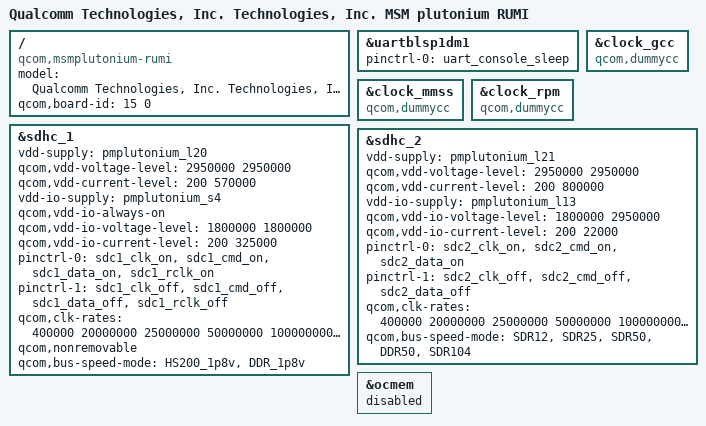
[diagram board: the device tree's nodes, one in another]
/* Copyright (c) 2013-2014, The Linux Foundation. All rights reserved.
 *
 * This program is free software; you can redistribute it and/or modify
 * it under the terms of the GNU General Public License version 2 and
 * only version 2 as published by the Free Software Foundation.
 *
 * This program is distributed in the hope that it will be useful,
 * but WITHOUT ANY WARRANTY; without even the implied warranty of
 * MERCHANTABILITY or FITNESS FOR A PARTICULAR PURPOSE.  See the
 * GNU General Public License for more details.
 */


/dts-v1/;

/memreserve/ 0x06000000 0x00001000;

#include "msmplutonium.dtsi"
#include "msmplutonium-pinctrl.dtsi"
/ {
	model = "Qualcomm Technologies, Inc. Technologies, Inc. MSM plutonium RUMI";
	compatible = "qcom,msmplutonium-rumi", "qcom,msmplutonium", "qcom,rumi";
	qcom,board-id = <15 0>;
};

&uartblsp1dm1 {
	status = "ok";
	pinctrl-names = "default";
	pinctrl-0 = <&uart_console_sleep>;
};

&clock_gcc {
	compatible = "qcom,dummycc";
	#clock-cells = <1>;
};

&clock_mmss {
	compatible = "qcom,dummycc";
	#clock-cells = <1>;
};

&clock_rpm {
	compatible = "qcom,dummycc";
	#clock-cells = <1>;
};

&sdhc_1 {
	vdd-supply = <&pmplutonium_l20>;
	qcom,vdd-voltage-level = <2950000 2950000>;
	qcom,vdd-current-level = <200 570000>;

	vdd-io-supply = <&pmplutonium_s4>;
	qcom,vdd-io-always-on;
	qcom,vdd-io-voltage-level = <1800000 1800000>;
	qcom,vdd-io-current-level = <200 325000>;

	pinctrl-names = "active", "sleep";
	pinctrl-0 = <&sdc1_clk_on &sdc1_cmd_on &sdc1_data_on &sdc1_rclk_on>;
	pinctrl-1 = <&sdc1_clk_off &sdc1_cmd_off &sdc1_data_off &sdc1_rclk_off>;

	qcom,clk-rates = <400000 20000000 25000000 50000000 100000000 200000000>;
	qcom,nonremovable;
	qcom,bus-speed-mode = "HS200_1p8v", "DDR_1p8v";
	status = "ok";
};

&sdhc_2 {
	vdd-supply = <&pmplutonium_l21>;
	qcom,vdd-voltage-level = <2950000 2950000>;
	qcom,vdd-current-level = <200 800000>;

	vdd-io-supply = <&pmplutonium_l13>;
	qcom,vdd-io-voltage-level = <1800000 2950000>;
	qcom,vdd-io-current-level = <200 22000>;

	pinctrl-names = "active", "sleep";
	pinctrl-0 = <&sdc2_clk_on &sdc2_cmd_on &sdc2_data_on>;
	pinctrl-1 = <&sdc2_clk_off &sdc2_cmd_off &sdc2_data_off>;

	qcom,clk-rates = <400000 20000000 25000000 50000000 100000000 200000000>;
	qcom,bus-speed-mode = "SDR12", "SDR25", "SDR50", "DDR50", "SDR104";
	status = "ok";
};

&ocmem {
	status = "disabled";
};
